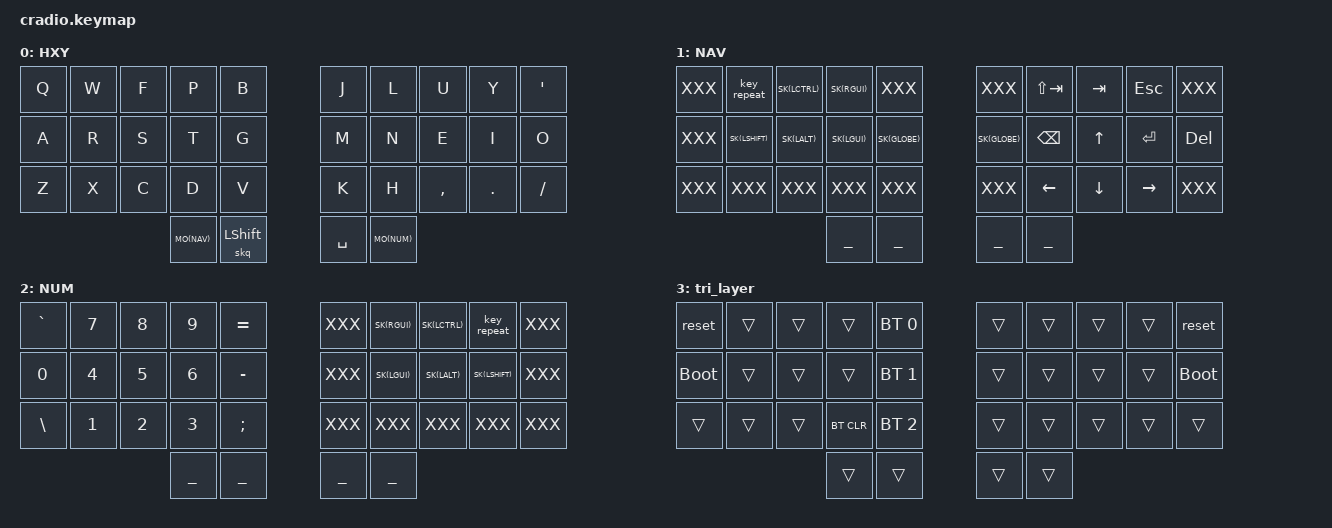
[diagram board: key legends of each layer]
// Copyright (c) 2022 The ZMK Contributors
// SPDX-License-Identifier: MIT

#include <behaviors.dtsi>
#include <dt-bindings/zmk/keys.h>
#include <dt-bindings/zmk/bt.h>

// Home row mods macro
#define HRML(k1,k2,k3,k4) &ht LSHFT k1  &ht LALT k2  &ht LCTRL k3  &ht LGUI k4
#define HRMR(k1,k2,k3,k4) &ht RGUI k1  &ht RCTRL k2  &ht RALT k3  &ht RSHFT k4

/ {
    behaviors {
        ht: hold_tap {
            label = "hold_tap";
            compatible = "zmk,behavior-hold-tap";
            #binding-cells = <2>;
            flavor = "tap-unless-interrupted";
            tapping-term-ms = <180>;
            quick-tap-ms = <150>;
            global-quick-tap;
            bindings = <&kp>, <&kp>;
        };
    };

    conditional_layers {
        compatible = "zmk,conditional-layers";
        tri_layer {
            if-layers = <1 2>;
            then-layer = <3>;
        };
    };

    keymap {
    compatible = "zmk,keymap";

    base_layer {
      label = "HXY";
      bindings = <
        // ╭─────────────┬─────────────┬─────────────┬─────────────┬─────────────╮   ╭─────────────┬─────────────┬─────────────┬─────────────┬─────────────╮
             &kp Q         &kp W         &kp F         &kp P         &kp B             &kp J         &kp L         &kp U         &kp Y         &kp SQT
        // ├─────────────┼─────────────┼─────────────┼─────────────┼─────────────┤   ├─────────────┼─────────────┼─────────────┼─────────────┼─────────────┤
             &kp A         &kp R         &kp S         &kp T         &kp G             &kp M         &kp N         &kp E         &kp I         &kp O
        // ├─────────────┼─────────────┼─────────────┼─────────────┼─────────────┤   ├─────────────┼─────────────┼─────────────┼─────────────┼─────────────┤
             &kp Z         &kp X         &kp C         &kp D         &kp V             &kp K         &kp H         &kp COMMA     &kp DOT       &kp SLASH
        // ╰─────────────┴─────────────┴─────────────┼─────────────┼─────────────┤   ├─────────────┼─────────────┼─────────────┴─────────────┴─────────────╯
                                                       MO(NAV)       &skq LSHIFT       &kp SPACE     MO(NUM)
        //                                           ╰─────────────┴─────────────╯   ╰─────────────┴─────────────╯
      >;
    };

    nav_layer {
      label = "NAV";
      bindings = <
        // ╭─────────────┬─────────────┬─────────────┬─────────────┬─────────────╮   ╭─────────────┬─────────────┬─────────────┬─────────────┬─────────────╮
             XXX           &key_repeat   SK(LCTRL)     SK(RGUI)      XXX               XXX           &kp LS(TAB)   &kp TAB       &kp ESC       XXX
        // ├─────────────┼─────────────┼─────────────┼─────────────┼─────────────┤   ├─────────────┼─────────────┼─────────────┼─────────────┼─────────────┤
             XXX           SK(LSHIFT)    SK(LALT)      SK(LGUI)      SK(GLOBE)         SK(GLOBE)     &kp BSPC      &kp UP        &kp ENTER     &kp DEL
        // ├─────────────┼─────────────┼─────────────┼─────────────┼─────────────┤   ├─────────────┼─────────────┼─────────────┼─────────────┼─────────────┤
             XXX           XXX           XXX           XXX           XXX               XXX           &kp LEFT      &kp DOWN      &kp RIGHT     XXX
        // ╰─────────────┴─────────────┴─────────────┼─────────────┼─────────────┤   ├─────────────┼─────────────┼─────────────┴─────────────┴─────────────╯
                                                       ___           ___               ___           ___
        //                                           ╰─────────────┴─────────────╯   ╰─────────────┴─────────────╯
      >;
    };

    num_layer {
      label = "NUM";
      bindings = <
        // ╭─────────────┬─────────────┬─────────────┬─────────────┬─────────────╮   ╭─────────────┬─────────────┬─────────────┬─────────────┬─────────────╮
             &kp GRAVE     &kp N7        &kp N8        &kp N9        &kp EQUAL         XXX           SK(RGUI)      SK(LCTRL)     &key_repeat   XXX
        // ├─────────────┼─────────────┼─────────────┼─────────────┼─────────────┤   ├─────────────┼─────────────┼─────────────┼─────────────┼─────────────┤
             &kp N0        &kp N4        &kp N5        &kp N6        &kp MINUS         XXX           SK(LGUI)      SK(LALT)      SK(LSHIFT)    XXX
        // ├─────────────┼─────────────┼─────────────┼─────────────┼─────────────┤   ├─────────────┼─────────────┼─────────────┼─────────────┼─────────────┤
             &kp BSLH      &kp N1        &kp N2        &kp N3        &kp SEMI          XXX           XXX           XXX           XXX           XXX
        // ╰─────────────┴─────────────┴─────────────┼─────────────┼─────────────┤   ├─────────────┼─────────────┼─────────────┴─────────────┴─────────────╯
                                                       ___           ___               ___           ___
        //                                           ╰─────────────┴─────────────╯   ╰─────────────┴─────────────╯
      >;
    };

        tri_layer {
            bindings = <
        //╭──────────┬──────────┬──────────┬──────────┬──────────╮   ╭──────────┬──────────┬──────────┬──────────┬──────────╮
        //│ RESET    │          │          │          │PROFILE 0 │   │          │          │          │          │  RESET   │
            &reset     &trans     &trans     &trans    &bt BT_SEL 0    &trans     &trans     &trans     &trans      &reset
        //├──────────┼──────────┼──────────┼──────────┼──────────┤   ├──────────┼──────────┼──────────┼──────────┼──────────┤
        //│BOOTLOADER│          │          │          │PROFILE 1 │   │          │          │          │          │BOOTLOADER│
          &bootloader  &trans     &trans     &trans    &bt BT_SEL 1    &trans     &trans     &trans     &trans    &bootloader
        //├──────────┼──────────┼──────────┼──────────┼──────────┤   ├──────────┼──────────┼──────────┼──────────┼──────────┤
        //│          │          │          │ CLEAR BT │PROFILE 2 │   │          │          │          │          │          │
            &trans     &trans     &trans    &bt BT_CLR &bt BT_SEL 2    &trans     &trans     &trans     &trans     &trans
        //╰──────────┴──────────┴──────────┼──────────┼──────────┤   ├──────────┼──────────┼──────────┴──────────┴──────────╯
                                             &trans     &trans         &trans     &trans
        //                                 ╰──────────┴──────────╯   ╰──────────┴──────────╯
            >;
        };
    };
};
